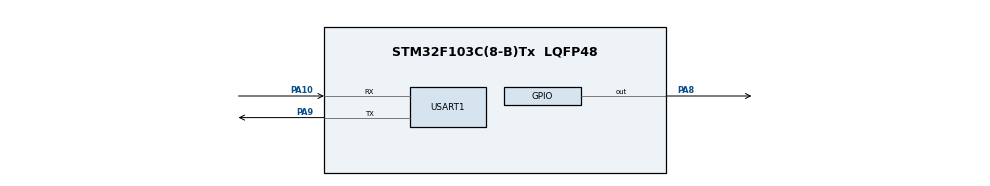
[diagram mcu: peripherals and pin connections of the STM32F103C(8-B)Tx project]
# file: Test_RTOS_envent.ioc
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FREERTOS.Events01=myEvent01,Dynamic,NULL;myEvent02,Dynamic,NULL
FREERTOS.Tasks01=Task01,42,128,StartTask01,Default,NULL,Dynamic,NULL,NULL;Task02,41,128,StartTask02,Default,NULL,Dynamic,NULL,NULL;Task03,24,128,StartTask03,Default,NULL,Dynamic,NULL,NULL
FREERTOS.configUSE_NEWLIB_REENTRANT=1
Mcu.Family=STM32F1
Mcu.Name=STM32F103C(8-B)Tx
Mcu.Package=LQFP48
NVIC.PriorityGroup=NVIC_PRIORITYGROUP_4
NVIC.TIM1_UP_IRQn=true\:15\:0\:false\:false\:true\:false\:false\:true\:true
NVIC.TimeBase=TIM1_UP_IRQn
NVIC.TimeBaseIP=TIM1
NVIC.USART1_IRQn=true\:5\:0\:false\:false\:true\:true\:true\:true\:true
PA10.Mode=Asynchronous
PA10.Signal=USART1_RX
PA13.Mode=Serial_Wire
PA13.Signal=SYS_JTMS-SWDIO
PA14.Mode=Serial_Wire
PA14.Signal=SYS_JTCK-SWCLK
PA8.PinState=GPIO_PIN_SET
PA8.Signal=GPIO_Output
PA9.Mode=Asynchronous
PA9.Signal=USART1_TX
ProjectManager.HeapSize=0x200
ProjectManager.StackSize=0x400
ProjectManager.TargetToolchain=STM32CubeIDE
RCC.APB1Freq_Value=8000000
RCC.APB2Freq_Value=8000000
USART1.VirtualMode=VM_ASYNC
VP_FREERTOS_VS_CMSIS_V2.Mode=CMSIS_V2
VP_SYS_VS_tim1.Mode=TIM1
board=custom

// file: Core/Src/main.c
/* USER CODE BEGIN Header */
/**
  ******************************************************************************
  * @file           : main.c
  * @brief          : Main program body
  ******************************************************************************
  * @attention
  *
  * Copyright (c) 2025 STMicroelectronics.
  * All rights reserved.
  *
  * This software is licensed under terms that can be found in the LICENSE file
  * in the root directory of this software component.
  * If no LICENSE file comes with this software, it is provided AS-IS.
  *
  ******************************************************************************
  */
/* USER CODE END Header */
#include "main.h"
#include "cmsis_os.h"

UART_HandleTypeDef huart1;
volatile uint32_t count = 0; // Biến đếm
/* Definitions for Task01 */
osThreadId_t Task01Handle;
const osThreadAttr_t Task01_attributes = {
  .name = "Task01",
  .stack_size = 128 * 4,
  .priority = (osPriority_t) osPriorityHigh2,
};
/* Definitions for Task02 */
osThreadId_t Task02Handle;
const osThreadAttr_t Task02_attributes = {
  .name = "Task02",
  .stack_size = 128 * 4,
  .priority = (osPriority_t) osPriorityHigh1,
};
/* Definitions for Task03 */
osThreadId_t Task03Handle;
const osThreadAttr_t Task03_attributes = {
  .name = "Task03",
  .stack_size = 128 * 4,
  .priority = (osPriority_t) osPriorityNormal,
};
/* Definitions for myEvent01 */
osEventFlagsId_t myEvent01Handle;
const osEventFlagsAttr_t myEvent01_attributes = {
  .name = "myEvent01"
};
/* Definitions for myEvent02 */
osEventFlagsId_t myEvent02Handle;
const osEventFlagsAttr_t myEvent02_attributes = {
  .name = "myEvent02"
};
/* USER CODE BEGIN PV */
int _write(int file, char *ptr, int len) {
    HAL_UART_Transmit(&huart1, (uint8_t *)ptr, len, HAL_MAX_DELAY);
    return len;
}
/* USER CODE END PV */

void SystemClock_Config(void);
static void MX_GPIO_Init(void);
static void MX_USART1_UART_Init(void);
void StartTask01(void *argument);
void StartTask02(void *argument);
void StartTask03(void *argument);

int main(void)
{

  /* MCU Configuration--------------------------------------------------------*/

  /* Reset of all peripherals, Initializes the Flash interface and the Systick. */
  HAL_Init();

  /* Configure the system clock */
  SystemClock_Config();

  /* Initialize all configured peripherals */
  MX_GPIO_Init();
  MX_USART1_UART_Init();

  /* Init scheduler */
  osKernelInitialize();

  /* Create the thread(s) */
  /* creation of Task01 */
  Task01Handle = osThreadNew(StartTask01, NULL, &Task01_attributes);

  /* creation of Task02 */
  Task02Handle = osThreadNew(StartTask02, NULL, &Task02_attributes);

  /* creation of Task03 */
  Task03Handle = osThreadNew(StartTask03, NULL, &Task03_attributes);

  /* Create the event(s) */
  /* creation of myEvent01 */
  myEvent01Handle = osEventFlagsNew(&myEvent01_attributes);

  /* creation of myEvent02 */
  myEvent02Handle = osEventFlagsNew(&myEvent02_attributes);

  /* Start scheduler */
  osKernelStart();

  /* We should never get here as control is now taken by the scheduler */

  /* Infinite loop */
  while (1)
  {

  }
}

void SystemClock_Config(void)
{
  RCC_OscInitTypeDef RCC_OscInitStruct = {0};
  RCC_ClkInitTypeDef RCC_ClkInitStruct = {0};

  /** Initializes the RCC Oscillators according to the specified parameters
  * in the RCC_OscInitTypeDef structure.
  */
  RCC_OscInitStruct.OscillatorType = RCC_OSCILLATORTYPE_HSI;
  RCC_OscInitStruct.HSIState = RCC_HSI_ON;
  RCC_OscInitStruct.HSICalibrationValue = RCC_HSICALIBRATION_DEFAULT;
  RCC_OscInitStruct.PLL.PLLState = RCC_PLL_NONE;
  if (HAL_RCC_OscConfig(&RCC_OscInitStruct) != HAL_OK)
  {
    Error_Handler();
  }

  /** Initializes the CPU, AHB and APB buses clocks
  */
  RCC_ClkInitStruct.ClockType = RCC_CLOCKTYPE_HCLK|RCC_CLOCKTYPE_SYSCLK
                              |RCC_CLOCKTYPE_PCLK1|RCC_CLOCKTYPE_PCLK2;
  RCC_ClkInitStruct.SYSCLKSource = RCC_SYSCLKSOURCE_HSI;
  RCC_ClkInitStruct.AHBCLKDivider = RCC_SYSCLK_DIV1;
  RCC_ClkInitStruct.APB1CLKDivider = RCC_HCLK_DIV1;
  RCC_ClkInitStruct.APB2CLKDivider = RCC_HCLK_DIV1;

  if (HAL_RCC_ClockConfig(&RCC_ClkInitStruct, FLASH_LATENCY_0) != HAL_OK)
  {
    Error_Handler();
  }
}

static void MX_USART1_UART_Init(void)
{

  huart1.Instance = USART1;
  huart1.Init.BaudRate = 115200;
  huart1.Init.WordLength = UART_WORDLENGTH_8B;
  huart1.Init.StopBits = UART_STOPBITS_1;
  huart1.Init.Parity = UART_PARITY_NONE;
  huart1.Init.Mode = UART_MODE_TX_RX;
  huart1.Init.HwFlowCtl = UART_HWCONTROL_NONE;
  huart1.Init.OverSampling = UART_OVERSAMPLING_16;
  if (HAL_UART_Init(&huart1) != HAL_OK)
  {
    Error_Handler();
  }

}

static void MX_GPIO_Init(void)
{
  GPIO_InitTypeDef GPIO_InitStruct = {0};

  /* GPIO Ports Clock Enable */
  __HAL_RCC_GPIOA_CLK_ENABLE();

  /*Configure GPIO pin Output Level */
  HAL_GPIO_WritePin(GPIOA, GPIO_PIN_8, GPIO_PIN_SET);

  /*Configure GPIO pin : PA8 */
  GPIO_InitStruct.Pin = GPIO_PIN_8;
  GPIO_InitStruct.Mode = GPIO_MODE_OUTPUT_PP;
  GPIO_InitStruct.Pull = GPIO_NOPULL;
  GPIO_InitStruct.Speed = GPIO_SPEED_FREQ_LOW;
  HAL_GPIO_Init(GPIOA, &GPIO_InitStruct);

}

void StartTask01(void *argument)
{
  /* USER CODE BEGIN 5 */
  /* Infinite loop */
  for(;;)
  {
	osEventFlagsWait(myEvent01Handle, (1 << 0), osFlagsWaitAny, osWaitForever); // Wait for DIV2 flag
	printf("Bien dem la so chan....\r\n\n");
    osDelay(1);
  }
  /* USER CODE END 5 */
}

void StartTask02(void *argument)
{
  /* USER CODE BEGIN StartTask02 */
  /* Infinite loop */
  for(;;)
  {
	  osEventFlagsWait(myEvent02Handle, (1 << 0) | (1 << 1), osFlagsWaitAll, osWaitForever);
	  printf("Bien dem chia het cho 6\r\n\n");
    osDelay(1);
  }
  /* USER CODE END StartTask02 */
}

void StartTask03(void *argument)
{
  /* USER CODE BEGIN StartTask03 */
  /* Infinite loop */
  for(;;)
  {
	  count++;

	          // Set event flags based on count
	          if (count % 2 == 0) {
	              osEventFlagsSet(myEvent01Handle, (1 << 0)); // Set DIV2 flag
	              osEventFlagsSet(myEvent02Handle, (1 << 0)); // Set DIV2 flag
	          }
	          if (count % 3 == 0) {
	              osEventFlagsSet(myEvent02Handle, (1 << 1)); // Set DIV6 flag
	          }
	          printf("Task 3: Count = %lu\r\n\n", count);
	          osEventFlagsClear(myEvent02Handle, (1 << 0) | (1 << 1));
	          osDelay(1000); // Delay 1 second
  }
  /* USER CODE END StartTask03 */
}

void HAL_TIM_PeriodElapsedCallback(TIM_HandleTypeDef *htim)
{
  if (htim->Instance == TIM1) {
    HAL_IncTick();
  }
}

void Error_Handler(void)
{
  __disable_irq();
  while (1)
  {
  }
}
